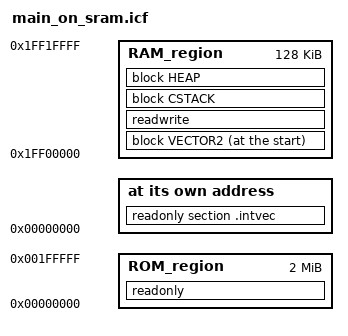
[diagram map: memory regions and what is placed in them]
/*###ICF### Section handled by ICF editor, don't touch! ****/
/*-Editor annotation file-*/
/* IcfEditorFile="$TOOLKIT_DIR$\config\ide\IcfEditor\cortex_v1_0.xml" */
/*-Specials-*/
define symbol __ICFEDIT_intvec_start__ = 0x00000000;
/*-Memory Regions-*/
define symbol __ICFEDIT_region_ROM_start__   = 0x00000000;
define symbol __ICFEDIT_region_ROM_end__     = 0x001FFFFF;
define symbol __ICFEDIT_region_RAM_start__   = 0x1FF00000;
define symbol __ICFEDIT_region_RAM_end__     = 0x1FF1FFFF;
/*-Sizes-*/
define symbol __ICFEDIT_size_cstack__   = 0x1800;
define symbol __ICFEDIT_size_heap__     = 0x2450;
/**** End of ICF editor section. ###ICF###*/


define memory mem with size = 4G;
define region ROM_region   = mem:[from __ICFEDIT_region_ROM_start__   to __ICFEDIT_region_ROM_end__];
define region RAM_region   = mem:[from __ICFEDIT_region_RAM_start__   to __ICFEDIT_region_RAM_end__];

define block CSTACK             with alignment = 8, size = __ICFEDIT_size_cstack__  { };
define block HEAP               with alignment = 8, size = __ICFEDIT_size_heap__    { };
define block VECTOR2            with alignment = 8, size = 0x400                    { };

//initialize by copy      { readonly, readwrite }    except  { readonly object startup_nuc505Series.o, readonly object system_nuc505Series.o };
initialize by copy      { readwrite, readonly object clk.o, readonly object nuc505_isr.o, readonly object layer3.o, readonly object layer12.o, readonly object synth.o, readonly object huffman.o, readonly object frame.o, readonly object bit.o, readonly object stream.o, readonly object timer.o, readonly object diskio.o, readonly object mp3.o };
//initialize manually     { section fastcode };
//initialize by copy with packing = none { section __DLIB_PERTHREAD }; // Required in a multi-threaded application
do not initialize       { section .noinit };

place at address mem:__ICFEDIT_intvec_start__ { readonly section .intvec };

place in ROM_region             { readonly };
place at start of RAM_region    { block VECTOR2 };
place in RAM_region             { readwrite, block CSTACK, block HEAP };
